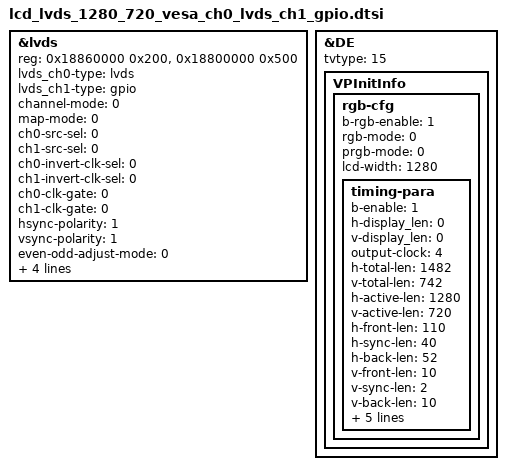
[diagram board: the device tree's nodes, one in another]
&lvds{
	reg = <0x18860000 0x200>, <0x18800000 0x500>;

	/*
	 * "lvds"		: LVDS screen
	 * "rgb888" 	: RGB screen
	 * "rgb666" 	: RGB screen
	 * "rgb565" 	: RGB screen
	 * "i2so"		: I2S OUT
	 * "gpio"		: only GPIO out
	 */
	lvds_ch0-type = "lvds";
	lvds_ch1-type = "gpio";

	/*
	 * 0: E_CHANNEL_MODE_SINGLE_IN_SINGLE_OUT ,
	 * 1: E_CHANNEL_MODE_SINGLE_IN_DUAL_OUT
	 */
	channel-mode = <0>;
	/*
	 * 0: VESA
	 * 1: JEDIA
	 */
	map-mode = <0>;
	ch0-src-sel = <0>;
	ch1-src-sel = <0>;
	ch0-invert-clk-sel = <0>;
	ch1-invert-clk-sel = <0>;
	ch0-clk-gate = <0>;
	ch1-clk-gate = <0>;
	hsync-polarity = <1>;
	vsync-polarity = <1>;
	/*
	 * 0: E_ADJUST_MODE_FRAME_START
	 * 1: E_ADJUST_MODE_HSYNC_POS
	 * 2: E_ADJUST_MODE_VSYNC_POS
	 */
	even-odd-adjust-mode = <0>;
	even-odd-init-value = <0>;
	/*
	 * 0: NOT SWAP
	 * 1: ERROR SWAP
	 * 2: FIX SWAP
	 */
	chx-swap-ctrl = <0>;
	/*
	 * 0: LVDS_LLD_PHY_DRIVE_STRENGTH_WEAKEST
	 * 1: LVDS_LLD_PHY_DRIVE_STRENGTH_NORMAL,
	 * 2: LVDS_LLD_PHY_DRIVE_STRENGTH_STRONGEST,
	 * */
	lvds-drive-strength = <1>;
	/*
	 * 0: E_SRC_SEL_FXDE = 0
	 * 1: E_SRC_SEL_4KDE
	 * 2: E_SRC_SEL_HDMI_RX
	 */
	src-sel = <CONFIG_DE4K_OUTPUT_SUPPORT>;
	// status = "okay";
};

&DE {
	tvtype = <15>;
	VPInitInfo {
		rgb-cfg{
			b-rgb-enable = <1>;
			/*
			 * 0: MODE_PRGB
			 * 1: MODE_SRGB
			 */
			rgb-mode = <0>;
			/*
			 * 0: MODE_PRGB_888_10bit
			 * 1: MODE_PRGB_666
			 */
			prgb-mode = <0>;
			lcd-width = <1280>;
			timing-para {
				/* bool type, 0 or 1*/
				b-enable = <1>;

				h-display_len = <0>;
				v-display_len = <0>;

				/*
				 * VPO_RGB_CLOCK_27M = 1,
				 * VPO_RGB_CLOCK_33M = 2,
				 * VPO_RGB_CLOCK_49M = 3,
				 * VPO_RGB_CLOCK_66M = 4,
				 * VPO_RGB_CLOCK_74M = 5,
				 * VPO_RGB_CLOCK_85M = 6,
				 * VPO_RGB_CLOCK_108M = 7,
				 * VPO_RGB_CLOCK_6_6M = 8,
				 * VPO_RGB_CLOCK_9M = 9,
				 * VPO_RGB_CLOCK_39_6M = 10,
				 * VPO_RGB_CLOCK_74_25M = 11,
				 * VPO_RGB_CLOCK_148_5M = 12,
				 * VPO_RGB_CLOCK_54M = 13,
				 * VPO_RGB_CLOCK_132M = 14,//H1600
				 * VPO_RGB_CLOCK_297M = 15,//H1600 only De4k
				 * VPO_RGB_CLOCK_DPLL = 0xFF,//H1600
				*/
				output-clock = <4>;

				h-total-len = <1482>;
				v-total-len = <742>;

				h-active-len = <1280>;
				v-active-len = <720>;

				h-front-len = <110>;
				h-sync-len = <40>;
				h-back-len = <52>;

				v-front-len = <10>;
				v-sync-len = <2>;
				v-back-len = <10>;

				/* bool type, 0 or 1*/
				h-sync-level = <1>;
				/* bool type, 0 or 1*/
				v-sync-level = <1>;

				/* bool type, 0 or 1*/
				active-polarity = <1>;
				frame-rate = <60000>;

				/*
				31	De_dig_pll_en
				25:16	DE_DIG_PLL_M_ctrl
				13:8	DE_DIG_PLL_N_ctrl
				5:0	DE_DIG_PLL_L_ctrl
				de_digpll_clock = 24 *(M+1)/((N+1)*(L+1))
				*/
				dpll-clock-reg-value = <0x0>;
			};
		};
	};
};
